# STM32N645 register map
File version: 1.0
CPU: CM55 r0p1, little endian, no MPU, FPU, vendor SysTick, 8 interrupt priority bits
Registers are 32-bit, read-write, reset 0x0 unless marked. A register's access mark holds for its fields unless they carry their own. Offsets are from the block's base; [hi:lo] are bit positions; {n}, {i} and the like mark numbered series.

## I2C1 — Inter-integrated circuit
Base 0x40005400
Same registers: I2C2 0x40005800, I2C3 0x40005C00, I2C4 0x46001C00, I2C1_S 0x50005400, I2C2_S 0x50005800, I2C3_S 0x50005C00, I2C4_S 0x56001C00
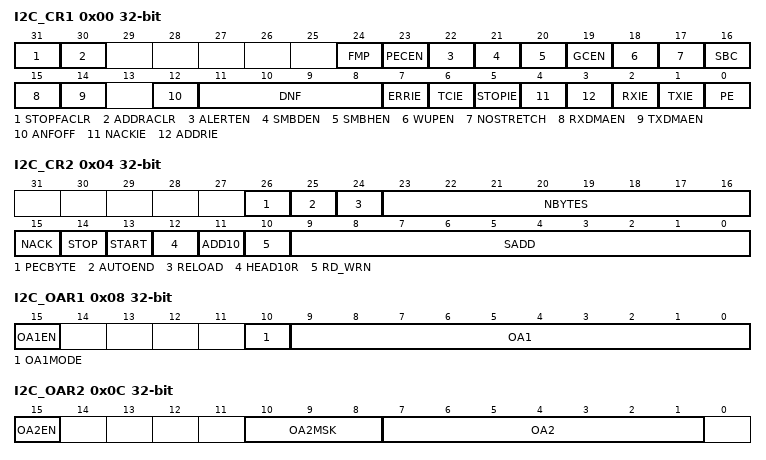
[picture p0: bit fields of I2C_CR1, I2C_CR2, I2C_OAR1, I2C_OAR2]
0x00 I2C_CR1 — I2C control register 1
  [31] STOPFACLR — STOP detection flag (STOPF) automatic clear
    0=STOPF flag is set by hardware and cleared by software by setting STOPCF bit; 1=STOPF flag remains cleared by hardware. This mode can be used in NOSTRETCH slave mode, to avoid the overrun error if the STOPF flag is not cleared before next data transmission. This allows a slave data management by DMA only, without any interrupt from peripheral.
  [30] ADDRACLR — Address match flag (ADDR) automatic clear
    0=ADDR flag is set by hardware and cleared by software by setting ADDRCF bit; 1=ADDR flag remains cleared by hardware. This mode can be used in slave mode, to avoid the ADDR clock stretching if the I2C enables only one slave address. This allows a slave data management by DMA only, without any interrupt from peripheral.
  [24] FMP — Fast-mode Plus 20 mA drive enable
    0=20 mA I/O drive disabled; 1=20 mA I/O drive enabled
  [23] PECEN — PEC enable
    0=PEC calculation disabled; 1=PEC calculation enabled
  [22] ALERTEN — SMBus alert enable
    0=The SMBus alert pin (SMBA) is not supported in host mode (SMBHEN=1). In device mode (SMBHEN=0), the SMBA pin is released and the Alert Response Address header is disabled (0001100x followed by NACK).; 1=The SMBus alert pin is supported in host mode (SMBHEN=1). In device mode (SMBHEN=0), the SMBA pin is driven low and the Alert Response Address header is enabled (0001100x followed by ACK).
  [21] SMBDEN — SMBus device default address enable
    0=Device default address disabled. Address 0b1100001x is NACKed.; 1=Device default address enabled. Address 0b1100001x is ACKed.
  [20] SMBHEN — SMBus host address enable
    0=Host address disabled. Address 0b0001000x is NACKed.; 1=Host address enabled. Address 0b0001000x is ACKed.
  [19] GCEN — General call enable
    0=General call disabled. Address 0b00000000 is NACKed.; 1=General call enabled. Address 0b00000000 is ACKed.
  [18] WUPEN — Wakeup from Stop mode enable
    0=Wakeup from Stop mode disable; 1=Wakeup from Stop mode enable
  [17] NOSTRETCH — Clock stretching disable
    0=Clock stretching enabled; 1=Clock stretching disabled
  [16] SBC — Slave byte control
    0=Slave byte control disabled; 1=Slave byte control enabled
  [15] RXDMAEN — DMA reception requests enable
    0=DMA mode disabled for reception; 1=DMA mode enabled for reception
  [14] TXDMAEN — DMA transmission requests enable
    0=DMA mode disabled for transmission; 1=DMA mode enabled for transmission
  [12] ANFOFF — Analog noise filter OFF
    0=Analog noise filter enabled; 1=Analog noise filter disabled
  [11:8] DNF — Digital noise filter
    0=Digital filter disabled; 1=Digital filter enabled and filtering capability up to 1 t less than sub>I2CCLK less than /sub>; 15=digital filter enabled and filtering capability up to15 t less than sub>I2CCLK less than /sub>
  [7] ERRIE — Error interrupts enable
    0=Error detection interrupts disabled; 1=Error detection interrupts enabled
  [6] TCIE — Transfer Complete interrupt enable
    0=Transfer Complete interrupt disabled; 1=Transfer Complete interrupt enabled
  [5] STOPIE — Stop detection Interrupt enable
    0=Stop detection (STOPF) interrupt disabled; 1=Stop detection (STOPF) interrupt enabled
  [4] NACKIE — Not acknowledge received Interrupt enable
    0=Not acknowledge (NACKF) received interrupts disabled; 1=Not acknowledge (NACKF) received interrupts enabled
  [3] ADDRIE — Address match Interrupt enable (slave only)
    0=Address match (ADDR) interrupts disabled; 1=Address match (ADDR) interrupts enabled
  [2] RXIE — RX Interrupt enable
    0=Receive (RXNE) interrupt disabled; 1=Receive (RXNE) interrupt enabled
  [1] TXIE — TX Interrupt enable
    0=Transmit (TXIS) interrupt disabled; 1=Transmit (TXIS) interrupt enabled
  [0] PE — Peripheral enable
    0=Peripheral disable; 1=Peripheral enable
0x04 I2C_CR2 — I2C control register 2
  [26] PECBYTE — Packet error checking byte
    0=No PEC transfer; 1=PEC transmission/reception is requested
  [25] AUTOEND — Automatic end mode (master mode)
    0=software end mode: TC flag is set when NBYTES data are transferred, stretching SCL low; 1=Automatic end mode: a STOP condition is automatically sent when NBYTES data are transferred
  [24] RELOAD — NBYTES reload mode
    0=The transfer is completed after the NBYTES data transfer (STOP or RESTART follows); 1=The transfer is not completed after the NBYTES data transfer (NBYTES is reloaded). TCR flag is set when NBYTES data are transferred, stretching SCL low.
  [23:16] NBYTES — Number of bytes
  [15] NACK — NACK generation (slave mode)
    0=an ACK is sent after current received byte; 1=a NACK is sent after current received byte
  [14] STOP — Stop generation (master mode)
    0=No Stop generation; 1=Stop generation after current byte transfer
  [13] START — Start generation
    0=No Start generation; 1=Restart/Start generation:
  [12] HEAD10R — 10-bit address header only read direction (master receiver mode)
    0=The master sends the complete 10 bit slave address read sequence: Start + 2 bytes 10bit address in write direction + Restart + 1st 7 bits of the 10 bit address in read direction; 1=The master only sends the 1st 7 bits of the 10 bit address, followed by Read direction
  [11] ADD10 — 10-bit addressing mode (master mode)
    0=The master operates in 7-bit addressing mode,; 1=The master operates in 10-bit addressing mode
  [10] RD_WRN — Transfer direction (master mode)
    0=Master requests a write transfer; 1=Master requests a read transfer
  [9:0] SADD — Slave address (master mode)
0x08 I2C_OAR1 — I2C own address 1 register
  [15] OA1EN — Own address 1 enable
    0=Own address 1 disabled. The received slave address OA1 is NACKed.; 1=Own address 1 enabled. The received slave address OA1 is ACKed.
  [10] OA1MODE — Own address 1 10-bit mode
    0=Own address 1 is a 7-bit address; 1=Own address 1 is a 10-bit address
  [9:0] OA1 — Interface own slave address
0x0C I2C_OAR2 — I2C own address 2 register
  [15] OA2EN — Own address 2 enable
    0=Own address 2 disabled. The received slave address OA2 is NACKed.; 1=Own address 2 enabled. The received slave address OA2 is ACKed.
  [10:8] OA2MSK — Own address 2 masks
    0=No mask; 1=OA2[1] is masked and don't care. Only OA2[7:2] are compared.; {v}=OA2[{v}:1] are masked and don't care. Only OA2[7:{v+1}] are compared. (v=2..5); 6=OA2[6:1] are masked and don't care. Only OA2[7] is compared.; 7=OA2[7:1] are masked and don't care. No comparison is done, and all (except reserved) 7-bit received addresses are acknowledged.
  [7:1] OA2 — Interface address
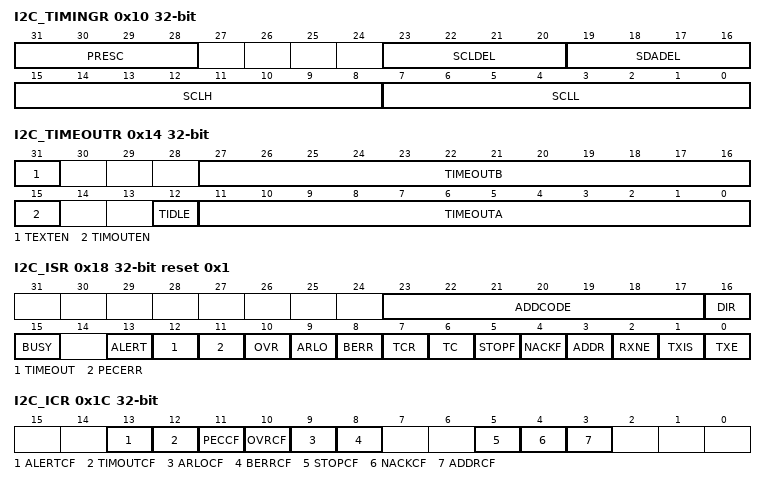
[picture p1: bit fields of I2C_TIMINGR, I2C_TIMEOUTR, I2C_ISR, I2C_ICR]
0x10 I2C_TIMINGR — I2C timing register
  [31:28] PRESC — Timing prescaler
  [23:20] SCLDEL — Data setup time
  [19:16] SDADEL — Data hold time
  [15:8] SCLH — SCL high period (master mode)
  [7:0] SCLL — SCL low period (master mode)
0x14 I2C_TIMEOUTR — I2C timeout register
  [31] TEXTEN — Extended clock timeout enable
    0=Extended clock timeout detection is disabled; 1=Extended clock timeout detection is enabled. When a cumulative SCL stretch for more than t less than sub>LOW:EXT less than /sub>is done by the I2C interface, a timeout error is detected (TIMEOUT=1).
  [27:16] TIMEOUTB — Bus timeout B
  [15] TIMOUTEN — Clock timeout enable
    0=SCL timeout detection is disabled; 1=SCL timeout detection is enabled: when SCL is low for more than t less than sub>TIMEOUT less than /sub> (TIDLE=0) or high for more than t less than sub>IDLE less than /sub>(TIDLE=1), a timeout error is detected (TIMEOUT=1)
  [12] TIDLE — Idle clock timeout detection
    0=TIMEOUTA is used to detect SCL low timeout; 1=TIMEOUTA is used to detect both SCL and SDA high timeout (bus idle condition)
  [11:0] TIMEOUTA — Bus Timeout A
0x18 I2C_ISR access per field reset 0x1 — I2C interrupt and status register
  [23:17] ADDCODE ro — Address match code (Slave mode)
  [16] DIR ro — Transfer direction (Slave mode)
    0=Write transfer, slave enters receiver mode; 1=Read transfer, slave enters transmitter mode
  [15] BUSY ro — Bus busy
  [13] ALERT ro — SMBus alert
  [12] TIMEOUT ro — Timeout or t less than sub>LOW less than /sub> detection flag
  [11] PECERR ro — PEC Error in reception
  [10] OVR ro — Overrun/Underrun (slave mode)
  [9] ARLO ro — Arbitration lost
  [8] BERR ro — Bus error
  [7] TCR ro — Transfer Complete Reload
  [6] TC ro — Transfer Complete (master mode)
  [5] STOPF ro — Stop detection flag
  [4] NACKF ro — Not Acknowledge received flag
  [3] ADDR ro — Address matched (slave mode)
  [2] RXNE ro — Receive data register not empty (receivers)
  [1] TXIS rw — Transmit interrupt status (transmitters)
  [0] TXE rw — Transmit data register empty (transmitters)
0x1C I2C_ICR wo — I2C interrupt clear register
  [13] ALERTCF — Alert flag clear
  [12] TIMOUTCF — Timeout detection flag clear
  [11] PECCF — PEC Error flag clear
  [10] OVRCF — Overrun/Underrun flag clear
  [9] ARLOCF — Arbitration lost flag clear
  [8] BERRCF — Bus error flag clear
  [5] STOPCF — STOP detection flag clear
  [4] NACKCF — Not Acknowledge flag clear
  [3] ADDRCF — Address matched flag clear
0x20 I2C_PECR ro — I2C PEC register
  [7:0] PEC — Packet error checking register
0x24 I2C_RXDR ro — I2C receive data register
  [7:0] RXDATA — 8-bit receive data
0x28 I2C_TXDR — I2C transmit data register
  [7:0] TXDATA — 8-bit transmit data
